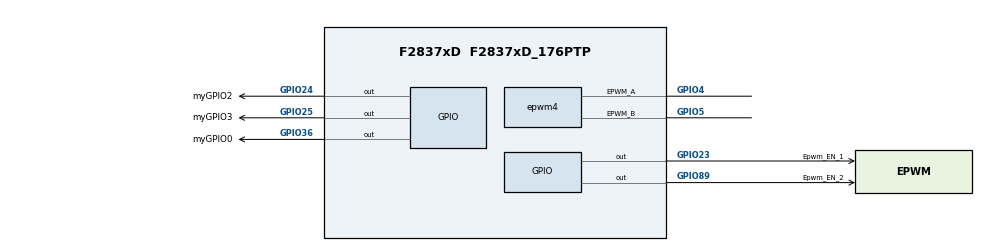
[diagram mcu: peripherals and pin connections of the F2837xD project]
/**
 *
 * @cliArgs --device "F2837xD" --part "F2837xD_176PTP" --package "F2837xD_176PTP" --context "CPU1" --product "C2000WARE@26.01.00.00"
 * @versions {"tool":"1.28.0+4696"}
 */

/**
 * Import the modules used in this configuration.
 */
const adc            = scripting.addModule("/driverlib/adc.js", {}, false);
const adc1           = adc.addInstance();
const adc2           = adc.addInstance();
const adc3           = adc.addInstance();
const device_support = scripting.addModule("/driverlib/device_support.js");
const dma            = scripting.addModule("/driverlib/dma.js", {}, false);
const dma1           = dma.addInstance();
const epwm           = scripting.addModule("/driverlib/epwm.js", {}, false);
const epwm1          = epwm.addInstance();
const epwm2          = epwm.addInstance();
const epwm3          = epwm.addInstance();
const epwm4          = epwm.addInstance();
const epwm5          = epwm.addInstance();
const epwm6          = epwm.addInstance();
const epwm7          = epwm.addInstance();
const gpio           = scripting.addModule("/driverlib/gpio.js", {}, false);
const gpio1          = gpio.addInstance();
const gpio2          = gpio.addInstance();
const gpio3          = gpio.addInstance();
const gpio4          = gpio.addInstance();
const gpio5          = gpio.addInstance();
const sysctl         = scripting.addModule("/driverlib/sysctl.js");
const FPUfastRTS     = scripting.addModule("/libraries/math/FPUfastRTS/FPUfastRTS.js", {}, false);
const FPUfastRTS1    = FPUfastRTS.addInstance();

/**
 * Write custom configuration values to the imported modules.
 */
adc1.$name               = "myADC0";
adc1.adcClockPrescaler   = "ADC_CLK_DIV_4_0";
adc1.enabledSOCs         = ["ADC_SOC_NUMBER2","ADC_SOC_NUMBER3","ADC_SOC_NUMBER4","ADC_SOC_NUMBER5"];
adc1.soc2Channel         = "ADC_CH_ADCIN2";
adc1.soc2SampleWindow    = 15;
adc1.soc2Trigger         = "ADC_TRIGGER_EPWM5_SOCA";
adc1.soc3Channel         = "ADC_CH_ADCIN3";
adc1.soc3SampleWindow    = 15;
adc1.soc3Trigger         = "ADC_TRIGGER_EPWM5_SOCA";
adc1.soc4Channel         = "ADC_CH_ADCIN4";
adc1.soc4SampleWindow    = 15;
adc1.soc4Trigger         = "ADC_TRIGGER_EPWM5_SOCA";
adc1.soc5Channel         = "ADC_CH_ADCIN5";
adc1.soc5SampleWindow    = 15;
adc1.soc5Trigger         = "ADC_TRIGGER_EPWM5_SOCA";
adc1.enableInterrupt1    = true;
adc1.useInterrupts       = false;
adc1.interruptPulseMode  = "ADC_PULSE_END_OF_CONV";
adc1.enabledInts         = ["ADC_INT_NUMBER1"];
adc1.interrupt1SOCSource = "ADC_SOC_NUMBER2";

adc2.$name             = "myADC1";
adc2.adcBase           = "ADCB_BASE";
adc2.adcClockPrescaler = "ADC_CLK_DIV_4_0";
adc2.enabledSOCs       = ["ADC_SOC_NUMBER0","ADC_SOC_NUMBER1"];
adc2.soc0Channel       = "ADC_CH_ADCIN2";
adc2.soc0SampleWindow  = 15;
adc2.soc1Channel       = "ADC_CH_ADCIN3";
adc2.soc1SampleWindow  = 15;
adc2.soc0Trigger       = "ADC_TRIGGER_EPWM5_SOCA";
adc2.soc1Trigger       = "ADC_TRIGGER_EPWM5_SOCA";

adc3.$name             = "myADC2";
adc3.adcBase           = "ADCC_BASE";
adc3.adcClockPrescaler = "ADC_CLK_DIV_4_0";
adc3.enabledSOCs       = ["ADC_SOC_NUMBER0","ADC_SOC_NUMBER1"];
adc3.soc0SampleWindow  = 15;
adc3.soc0Channel       = "ADC_CH_ADCIN2";
adc3.soc1Channel       = "ADC_CH_ADCIN3";
adc3.soc1SampleWindow  = 15;
adc3.soc1Trigger       = "ADC_TRIGGER_EPWM5_SOCA";
adc3.soc0Trigger       = "ADC_TRIGGER_EPWM5_SOCA";

const multiplier4         = system.clockTree["PLL_IMULT"];
multiplier4.multiplyValue = 20;

const pinFunction3     = system.clockTree["XTAL"];
pinFunction3.XTAL_Freq = 20;

dma1.$name                = "myDMA0";
dma1.emulationMode        = "DMA_EMULATION_FREE_RUN";
dma1.startChannel         = true;
dma1.srcBurstStep         = 1;
dma1.srcAddressManual     = 0xB02;
dma1.destAddressInputMode = "VARIABLE";
dma1.destBurstStep        = 1;
dma1.destAddressVariable  = "adc1_DATA_dma";
dma1.srcAddressVariable   = "datafrom";
dma1.srcAddressInputMode  = "VARIABLE";
dma1.burstSize            = 4;
dma1.srcTransferStep      = -4;
dma1.destTransferStep     = -4;
dma1.continuousModeConfig = "DMA_CFG_CONTINUOUS_ENABLE";
dma1.triggerSource        = "DMA_TRIGGER_EPWM5SOCA";

epwm1.epwmTimebase_counterMode                                 = "EPWM_COUNTER_MODE_UP";
epwm1.epwmActionQualifier_EPWM_AQ_OUTPUT_A_shadowMode          = true;
epwm1.epwmActionQualifier_EPWM_AQ_OUTPUT_B_shadowMode          = true;
epwm1.epwmDeadband_enableFED                                   = true;
epwm1.epwmDeadband_polarityFED                                 = "EPWM_DB_POLARITY_ACTIVE_LOW";
epwm1.epwmDeadband_enableRED                                   = true;
epwm1.epwmDeadband_inputFED                                    = "EPWM_DB_INPUT_EPWMB";
epwm1.$name                                                    = "myEPWM1";
epwm1.epwmTimebase_hsClockDiv                                  = "EPWM_HSCLOCK_DIVIDER_1";
epwm1.epwmTimebase_syncOutPulseMode                            = "EPWM_SYNC_OUT_PULSE_ON_COUNTER_ZERO";
epwm1.epwmActionQualifier_EPWM_AQ_OUTPUT_A_ON_TIMEBASE_UP_CMPB = "EPWM_AQ_OUTPUT_HIGH";
epwm1.epwmEventTrigger_enableInterrupt                         = true;
epwm1.epwmEventTrigger_registerInterrupts                      = true;
epwm1.epwmEventTrigger_interruptSource                         = "EPWM_INT_TBCTR_ZERO";
epwm1.epwmCounterCompare_cmpA                                  = 250;
epwm1.epwmCounterCompare_cmpB                                  = 500;
epwm1.epwmEventTrigger_interruptEventCount                     = "4";
epwm1.epwmActionQualifier_EPWM_AQ_OUTPUT_B_ON_TIMEBASE_ZERO    = "EPWM_AQ_OUTPUT_LOW";
epwm1.epwmGlobalLoad_gld                                       = true;
epwm1.epwmGlobalLoad_gldPeriod                                 = "1";
epwm1.epwmGlobalLoad_enableOneShot                             = true;
epwm1.epwmGlobalLoad_oneShotMode                               = true;
epwm1.epwmCounterCompare_cmpAGld                               = true;
epwm1.epwmCounterCompare_cmpBGld                               = true;
epwm1.epwmActionQualifier_continousSwForceReloadModeGld        = true;
epwm1.epwmActionQualifier_EPWM_AQ_OUTPUT_A_gld                 = true;
epwm1.epwmActionQualifier_EPWM_AQ_OUTPUT_B_gld                 = true;
epwm1.epwmActionQualifier_EPWM_AQ_OUTPUT_A_ON_TIMEBASE_ZERO    = "EPWM_AQ_OUTPUT_HIGH";
epwm1.epwmActionQualifier_EPWM_AQ_OUTPUT_A_ON_TIMEBASE_UP_CMPA = "EPWM_AQ_OUTPUT_LOW";
epwm1.epwmActionQualifier_EPWM_AQ_OUTPUT_B_ON_TIMEBASE_UP_CMPA = "EPWM_AQ_OUTPUT_LOW";
epwm1.epwmActionQualifier_EPWM_AQ_OUTPUT_B_ON_TIMEBASE_UP_CMPB = "EPWM_AQ_OUTPUT_HIGH";
epwm1.epwmTimebase_period                                      = 2000;
epwm1.epwmDeadband_delayRED                                    = 10;
epwm1.epwmDeadband_delayFED                                    = 10;
epwm1.epwmGlobalLoad_gldMode                                   = "EPWM_GL_LOAD_PULSE_CNTR_PERIOD";
epwm1.epwmActionQualifier_continousSwForceReloadMode           = "EPWM_AQ_SW_SH_LOAD_ON_CNTR_PERIOD";
epwm1.epwm.$assign                                             = "EPWM1";
epwm1.epwmInt.enableInterrupt                                  = true;

epwm2.$name                                                    = "myEPWM2";
epwm2.epwmTimebase_hsClockDiv                                  = "EPWM_HSCLOCK_DIVIDER_1";
epwm2.epwmTimebase_periodLoadEvent                             = "EPWM_SHADOW_LOAD_MODE_COUNTER_SYNC";
epwm2.epwmTimebase_phaseEnable                                 = true;
epwm2.epwmTimebase_counterMode                                 = "EPWM_COUNTER_MODE_UP";
epwm2.epwmDeadband_inputFED                                    = "EPWM_DB_INPUT_EPWMB";
epwm2.epwmDeadband_polarityFED                                 = "EPWM_DB_POLARITY_ACTIVE_LOW";
epwm2.epwmDeadband_enableRED                                   = true;
epwm2.epwmDeadband_enableFED                                   = true;
epwm2.epwmDeadband_delayRED                                    = 10;
epwm2.epwmDeadband_delayFED                                    = 10;
epwm2.epwmActionQualifier_EPWM_AQ_OUTPUT_A_ON_TIMEBASE_UP_CMPB = "EPWM_AQ_OUTPUT_HIGH";
epwm2.epwmCounterCompare_cmpB                                  = 750;
epwm2.epwmCounterCompare_cmpA                                  = 500;
epwm2.epwmTimebase_syncOutPulseMode                            = "EPWM_SYNC_OUT_PULSE_ON_EPWMxSYNCIN";
epwm2.epwmActionQualifier_EPWM_AQ_OUTPUT_B_ON_TIMEBASE_ZERO    = "EPWM_AQ_OUTPUT_LOW";
epwm2.epwmGlobalLoad_gld                                       = true;
epwm2.epwmGlobalLoad_gldPeriod                                 = "1";
epwm2.epwmGlobalLoad_enableOneShot                             = true;
epwm2.epwmGlobalLoad_oneShotMode                               = true;
epwm2.epwmGlobalLoad_globalePWMLoadLink                        = "EPWM_LINK_WITH_EPWM_1";
epwm2.epwmActionQualifier_EPWM_AQ_OUTPUT_A_shadowMode          = true;
epwm2.epwmActionQualifier_EPWM_AQ_OUTPUT_B_shadowMode          = true;
epwm2.epwmActionQualifier_EPWM_AQ_OUTPUT_A_gld                 = true;
epwm2.epwmActionQualifier_EPWM_AQ_OUTPUT_B_gld                 = true;
epwm2.epwmActionQualifier_continousSwForceReloadModeGld        = true;
epwm2.epwmCounterCompare_cmpAGld                               = true;
epwm2.epwmCounterCompare_cmpBGld                               = true;
epwm2.epwmActionQualifier_EPWM_AQ_OUTPUT_A_ON_TIMEBASE_ZERO    = "EPWM_AQ_OUTPUT_LOW";
epwm2.epwmActionQualifier_EPWM_AQ_OUTPUT_A_ON_TIMEBASE_UP_CMPA = "EPWM_AQ_OUTPUT_HIGH";
epwm2.epwmActionQualifier_EPWM_AQ_OUTPUT_B_ON_TIMEBASE_UP_CMPA = "EPWM_AQ_OUTPUT_HIGH";
epwm2.epwmActionQualifier_EPWM_AQ_OUTPUT_B_ON_TIMEBASE_UP_CMPB = "EPWM_AQ_OUTPUT_LOW";
epwm2.epwmTimebase_period                                      = 2000;
epwm2.epwmGlobalLoad_gldMode                                   = "EPWM_GL_LOAD_PULSE_CNTR_PERIOD";
epwm2.epwm.$assign                                             = "EPWM2";

epwm3.$name                                             = "myEPWM5";
epwm3.epwmTimebase_hsClockDiv                           = "EPWM_HSCLOCK_DIVIDER_1";
epwm3.epwmTimebase_periodLoadEvent                      = "EPWM_SHADOW_LOAD_MODE_COUNTER_SYNC";
epwm3.epwmTimebase_phaseEnable                          = true;
epwm3.epwmTimebase_counterMode                          = "EPWM_COUNTER_MODE_UP";
epwm3.epwmTimebase_syncOutPulseMode                     = "EPWM_SYNC_OUT_PULSE_ON_COUNTER_ZERO";
epwm3.epwmActionQualifier_EPWM_AQ_OUTPUT_A_shadowMode   = true;
epwm3.epwmDeadband_inputFED                             = "EPWM_DB_INPUT_EPWMB";
epwm3.epwmDeadband_polarityFED                          = "EPWM_DB_POLARITY_ACTIVE_LOW";
epwm3.epwmDeadband_enableRED                            = true;
epwm3.epwmDeadband_enableFED                            = true;
epwm3.epwmDeadband_delayRED                             = 10;
epwm3.epwmDeadband_delayFED                             = 10;
epwm3.epwmEventTrigger_EPWM_SOC_A_triggerEnable         = true;
epwm3.epwmCounterCompare_cmpB                           = 1;
epwm3.epwmEventTrigger_EPWM_SOC_A_triggerEventPrescalar = "4";
epwm3.epwmEventTrigger_EPWM_SOC_A_triggerSource         = "EPWM_SOC_TBCTR_U_CMPA";
epwm3.epwmTimebase_period                               = 2000;
epwm3.epwmCounterCompare_cmpA                           = 500;
epwm3.epwm.$assign                                      = "EPWM5";

epwm4.$name                                                    = "myEPWM3";
epwm4.epwmTimebase_counterMode                                 = "EPWM_COUNTER_MODE_UP";
epwm4.epwmActionQualifier_EPWM_AQ_OUTPUT_A_shadowMode          = true;
epwm4.epwmActionQualifier_EPWM_AQ_OUTPUT_B_shadowMode          = true;
epwm4.epwmDeadband_enableFED                                   = true;
epwm4.epwmDeadband_polarityFED                                 = "EPWM_DB_POLARITY_ACTIVE_LOW";
epwm4.epwmDeadband_enableRED                                   = true;
epwm4.epwmDeadband_inputFED                                    = "EPWM_DB_INPUT_EPWMB";
epwm4.epwmDeadband_delayRED                                    = 10;
epwm4.epwmDeadband_delayFED                                    = 10;
epwm4.epwmTimebase_hsClockDiv                                  = "EPWM_HSCLOCK_DIVIDER_1";
epwm4.epwmActionQualifier_EPWM_AQ_OUTPUT_A_ON_TIMEBASE_UP_CMPB = "EPWM_AQ_OUTPUT_HIGH";
epwm4.epwmCounterCompare_cmpA                                  = 250;
epwm4.epwmCounterCompare_cmpB                                  = 500;
epwm4.epwmActionQualifier_EPWM_AQ_OUTPUT_B_ON_TIMEBASE_ZERO    = "EPWM_AQ_OUTPUT_LOW";
epwm4.epwmGlobalLoad_gld                                       = true;
epwm4.epwmGlobalLoad_gldPeriod                                 = "1";
epwm4.epwmGlobalLoad_enableOneShot                             = true;
epwm4.epwmGlobalLoad_oneShotMode                               = true;
epwm4.epwmCounterCompare_cmpAGld                               = true;
epwm4.epwmCounterCompare_cmpBGld                               = true;
epwm4.epwmActionQualifier_continousSwForceReloadModeGld        = true;
epwm4.epwmActionQualifier_EPWM_AQ_OUTPUT_A_gld                 = true;
epwm4.epwmActionQualifier_EPWM_AQ_OUTPUT_B_gld                 = true;
epwm4.epwmGlobalLoad_globalePWMLoadLink                        = "EPWM_LINK_WITH_EPWM_1";
epwm4.epwmTimebase_phaseEnable                                 = true;
epwm4.epwmTimebase_syncOutPulseMode                            = "EPWM_SYNC_OUT_PULSE_ON_EPWMxSYNCIN";
epwm4.epwmActionQualifier_EPWM_AQ_OUTPUT_A_ON_TIMEBASE_ZERO    = "EPWM_AQ_OUTPUT_HIGH";
epwm4.epwmActionQualifier_EPWM_AQ_OUTPUT_A_ON_TIMEBASE_UP_CMPA = "EPWM_AQ_OUTPUT_LOW";
epwm4.epwmActionQualifier_EPWM_AQ_OUTPUT_B_ON_TIMEBASE_UP_CMPA = "EPWM_AQ_OUTPUT_LOW";
epwm4.epwmActionQualifier_EPWM_AQ_OUTPUT_B_ON_TIMEBASE_UP_CMPB = "EPWM_AQ_OUTPUT_HIGH";
epwm4.epwmTimebase_period                                      = 2000;
epwm4.epwmTimebase_phaseShift                                  = 667;
epwm4.epwmGlobalLoad_gldMode                                   = "EPWM_GL_LOAD_PULSE_CNTR_PERIOD";
epwm4.epwm.epwm_aPin.$assign                                   = "GPIO4";
epwm4.epwm.epwm_bPin.$assign                                   = "GPIO5";

epwm5.$name                                                    = "myEPWM4";
epwm5.epwmTimebase_hsClockDiv                                  = "EPWM_HSCLOCK_DIVIDER_1";
epwm5.epwmTimebase_periodLoadEvent                             = "EPWM_SHADOW_LOAD_MODE_COUNTER_SYNC";
epwm5.epwmTimebase_phaseEnable                                 = true;
epwm5.epwmTimebase_counterMode                                 = "EPWM_COUNTER_MODE_UP";
epwm5.epwmDeadband_inputFED                                    = "EPWM_DB_INPUT_EPWMB";
epwm5.epwmDeadband_polarityFED                                 = "EPWM_DB_POLARITY_ACTIVE_LOW";
epwm5.epwmDeadband_enableRED                                   = true;
epwm5.epwmDeadband_enableFED                                   = true;
epwm5.epwmDeadband_delayRED                                    = 10;
epwm5.epwmDeadband_delayFED                                    = 10;
epwm5.epwmActionQualifier_EPWM_AQ_OUTPUT_A_ON_TIMEBASE_UP_CMPB = "EPWM_AQ_OUTPUT_HIGH";
epwm5.epwmCounterCompare_cmpB                                  = 750;
epwm5.epwmCounterCompare_cmpA                                  = 500;
epwm5.epwmTimebase_syncOutPulseMode                            = "EPWM_SYNC_OUT_PULSE_ON_EPWMxSYNCIN";
epwm5.epwmActionQualifier_EPWM_AQ_OUTPUT_B_ON_TIMEBASE_ZERO    = "EPWM_AQ_OUTPUT_LOW";
epwm5.epwmGlobalLoad_gld                                       = true;
epwm5.epwmGlobalLoad_gldPeriod                                 = "1";
epwm5.epwmGlobalLoad_enableOneShot                             = true;
epwm5.epwmGlobalLoad_oneShotMode                               = true;
epwm5.epwmGlobalLoad_globalePWMLoadLink                        = "EPWM_LINK_WITH_EPWM_1";
epwm5.epwmActionQualifier_EPWM_AQ_OUTPUT_A_shadowMode          = true;
epwm5.epwmActionQualifier_EPWM_AQ_OUTPUT_B_shadowMode          = true;
epwm5.epwmActionQualifier_EPWM_AQ_OUTPUT_A_gld                 = true;
epwm5.epwmActionQualifier_EPWM_AQ_OUTPUT_B_gld                 = true;
epwm5.epwmActionQualifier_continousSwForceReloadModeGld        = true;
epwm5.epwmCounterCompare_cmpAGld                               = true;
epwm5.epwmCounterCompare_cmpBGld                               = true;
epwm5.epwmActionQualifier_EPWM_AQ_OUTPUT_A_ON_TIMEBASE_ZERO    = "EPWM_AQ_OUTPUT_LOW";
epwm5.epwmActionQualifier_EPWM_AQ_OUTPUT_A_ON_TIMEBASE_UP_CMPA = "EPWM_AQ_OUTPUT_HIGH";
epwm5.epwmActionQualifier_EPWM_AQ_OUTPUT_B_ON_TIMEBASE_UP_CMPA = "EPWM_AQ_OUTPUT_HIGH";
epwm5.epwmActionQualifier_EPWM_AQ_OUTPUT_B_ON_TIMEBASE_UP_CMPB = "EPWM_AQ_OUTPUT_LOW";
epwm5.epwmTimebase_period                                      = 2000;
epwm5.epwmTimebase_phaseShift                                  = 667;
epwm5.epwmGlobalLoad_gldMode                                   = "EPWM_GL_LOAD_PULSE_CNTR_PERIOD";
epwm5.epwm.$assign                                             = "EPWM4";

epwm6.epwmTimebase_counterMode                                 = "EPWM_COUNTER_MODE_UP";
epwm6.epwmActionQualifier_EPWM_AQ_OUTPUT_A_shadowMode          = true;
epwm6.epwmActionQualifier_EPWM_AQ_OUTPUT_B_shadowMode          = true;
epwm6.epwmDeadband_enableFED                                   = true;
epwm6.epwmDeadband_polarityFED                                 = "EPWM_DB_POLARITY_ACTIVE_LOW";
epwm6.epwmDeadband_enableRED                                   = true;
epwm6.epwmDeadband_inputFED                                    = "EPWM_DB_INPUT_EPWMB";
epwm6.epwmDeadband_delayRED                                    = 10;
epwm6.epwmDeadband_delayFED                                    = 10;
epwm6.$name                                                    = "myEPWM6";
epwm6.epwmTimebase_hsClockDiv                                  = "EPWM_HSCLOCK_DIVIDER_1";
epwm6.epwmTimebase_syncOutPulseMode                            = "EPWM_SYNC_OUT_PULSE_ON_COUNTER_ZERO";
epwm6.epwmActionQualifier_EPWM_AQ_OUTPUT_A_ON_TIMEBASE_UP_CMPB = "EPWM_AQ_OUTPUT_HIGH";
epwm6.epwmCounterCompare_cmpA                                  = 250;
epwm6.epwmCounterCompare_cmpB                                  = 500;
epwm6.epwmActionQualifier_EPWM_AQ_OUTPUT_B_ON_TIMEBASE_ZERO    = "EPWM_AQ_OUTPUT_LOW";
epwm6.epwmGlobalLoad_gld                                       = true;
epwm6.epwmGlobalLoad_gldPeriod                                 = "1";
epwm6.epwmGlobalLoad_enableOneShot                             = true;
epwm6.epwmGlobalLoad_oneShotMode                               = true;
epwm6.epwmCounterCompare_cmpAGld                               = true;
epwm6.epwmCounterCompare_cmpBGld                               = true;
epwm6.epwmActionQualifier_continousSwForceReloadModeGld        = true;
epwm6.epwmActionQualifier_EPWM_AQ_OUTPUT_A_gld                 = true;
epwm6.epwmActionQualifier_EPWM_AQ_OUTPUT_B_gld                 = true;
epwm6.epwmGlobalLoad_globalePWMLoadLink                        = "EPWM_LINK_WITH_EPWM_1";
epwm6.epwmTimebase_phaseEnable                                 = true;
epwm6.epwmActionQualifier_EPWM_AQ_OUTPUT_A_ON_TIMEBASE_ZERO    = "EPWM_AQ_OUTPUT_HIGH";
epwm6.epwmActionQualifier_EPWM_AQ_OUTPUT_A_ON_TIMEBASE_UP_CMPA = "EPWM_AQ_OUTPUT_LOW";
epwm6.epwmActionQualifier_EPWM_AQ_OUTPUT_B_ON_TIMEBASE_UP_CMPA = "EPWM_AQ_OUTPUT_LOW";
epwm6.epwmActionQualifier_EPWM_AQ_OUTPUT_B_ON_TIMEBASE_UP_CMPB = "EPWM_AQ_OUTPUT_HIGH";
epwm6.epwmTimebase_period                                      = 2000;
epwm6.epwmTimebase_phaseShift                                  = 1333;
epwm6.epwmGlobalLoad_gldMode                                   = "EPWM_GL_LOAD_PULSE_CNTR_PERIOD";
epwm6.epwm.$assign                                             = "EPWM6";

epwm7.$name                                                    = "myEPWM7";
epwm7.epwmTimebase_hsClockDiv                                  = "EPWM_HSCLOCK_DIVIDER_1";
epwm7.epwmTimebase_periodLoadEvent                             = "EPWM_SHADOW_LOAD_MODE_COUNTER_SYNC";
epwm7.epwmTimebase_phaseEnable                                 = true;
epwm7.epwmTimebase_counterMode                                 = "EPWM_COUNTER_MODE_UP";
epwm7.epwmDeadband_inputFED                                    = "EPWM_DB_INPUT_EPWMB";
epwm7.epwmDeadband_polarityFED                                 = "EPWM_DB_POLARITY_ACTIVE_LOW";
epwm7.epwmDeadband_enableRED                                   = true;
epwm7.epwmDeadband_enableFED                                   = true;
epwm7.epwmDeadband_delayRED                                    = 10;
epwm7.epwmDeadband_delayFED                                    = 10;
epwm7.epwmActionQualifier_EPWM_AQ_OUTPUT_A_ON_TIMEBASE_UP_CMPB = "EPWM_AQ_OUTPUT_HIGH";
epwm7.epwmCounterCompare_cmpB                                  = 750;
epwm7.epwmCounterCompare_cmpA                                  = 500;
epwm7.epwmTimebase_syncOutPulseMode                            = "EPWM_SYNC_OUT_PULSE_ON_EPWMxSYNCIN";
epwm7.epwmActionQualifier_EPWM_AQ_OUTPUT_B_ON_TIMEBASE_ZERO    = "EPWM_AQ_OUTPUT_LOW";
epwm7.epwmGlobalLoad_gld                                       = true;
epwm7.epwmGlobalLoad_gldPeriod                                 = "1";
epwm7.epwmGlobalLoad_enableOneShot                             = true;
epwm7.epwmGlobalLoad_oneShotMode                               = true;
epwm7.epwmGlobalLoad_globalePWMLoadLink                        = "EPWM_LINK_WITH_EPWM_1";
epwm7.epwmActionQualifier_EPWM_AQ_OUTPUT_A_shadowMode          = true;
epwm7.epwmActionQualifier_EPWM_AQ_OUTPUT_B_shadowMode          = true;
epwm7.epwmActionQualifier_EPWM_AQ_OUTPUT_A_gld                 = true;
epwm7.epwmActionQualifier_EPWM_AQ_OUTPUT_B_gld                 = true;
epwm7.epwmActionQualifier_continousSwForceReloadModeGld        = true;
epwm7.epwmCounterCompare_cmpAGld                               = true;
epwm7.epwmCounterCompare_cmpBGld                               = true;
epwm7.epwmActionQualifier_EPWM_AQ_OUTPUT_A_ON_TIMEBASE_ZERO    = "EPWM_AQ_OUTPUT_LOW";
epwm7.epwmActionQualifier_EPWM_AQ_OUTPUT_A_ON_TIMEBASE_UP_CMPA = "EPWM_AQ_OUTPUT_HIGH";
epwm7.epwmActionQualifier_EPWM_AQ_OUTPUT_B_ON_TIMEBASE_UP_CMPA = "EPWM_AQ_OUTPUT_HIGH";
epwm7.epwmActionQualifier_EPWM_AQ_OUTPUT_B_ON_TIMEBASE_UP_CMPB = "EPWM_AQ_OUTPUT_LOW";
epwm7.epwmTimebase_period                                      = 2000;
epwm7.epwmTimebase_phaseShift                                  = 1333;
epwm7.epwmGlobalLoad_gldMode                                   = "EPWM_GL_LOAD_PULSE_CNTR_PERIOD";
epwm7.epwm.$assign                                             = "EPWM7";

gpio1.$name           = "myGPIO0";
gpio1.direction       = "GPIO_DIR_MODE_OUT";
gpio1.gpioPin.$assign = "GPIO36";

gpio2.direction       = "GPIO_DIR_MODE_OUT";
gpio2.$name           = "Epwm_EN_1";
gpio2.gpioPin.$assign = "GPIO23";

gpio3.$name           = "myGPIO2";
gpio3.direction       = "GPIO_DIR_MODE_OUT";
gpio3.gpioPin.$assign = "GPIO24";

gpio4.$name           = "myGPIO3";
gpio4.direction       = "GPIO_DIR_MODE_OUT";
gpio4.gpioPin.$assign = "GPIO25";

gpio5.direction       = "GPIO_DIR_MODE_OUT";
gpio5.$name           = "Epwm_EN_2";
gpio5.gpioPin.$assign = "GPIO89";

sysctl.splitCode = true;

FPUfastRTS1.$name = "myFFR0";

/**
 * Pinmux solution for unlocked pins/peripherals. This ensures that minor changes to the automatic solver in a future
 * version of the tool will not impact the pinmux you originally saw.  These lines can be completely deleted in order to
 * re-solve from scratch.
 */
epwm1.epwm.epwm_aPin.$suggestSolution = "GPIO0";
epwm1.epwm.epwm_bPin.$suggestSolution = "GPIO1";
epwm2.epwm.epwm_aPin.$suggestSolution = "GPIO2";
epwm2.epwm.epwm_bPin.$suggestSolution = "GPIO3";
epwm3.epwm.epwm_aPin.$suggestSolution = "GPIO8";
epwm3.epwm.epwm_bPin.$suggestSolution = "GPIO9";
epwm4.epwm.$suggestSolution           = "EPWM3";
epwm5.epwm.epwm_aPin.$suggestSolution = "GPIO6";
epwm5.epwm.epwm_bPin.$suggestSolution = "GPIO7";
epwm6.epwm.epwm_aPin.$suggestSolution = "GPIO10";
epwm6.epwm.epwm_bPin.$suggestSolution = "GPIO11";
epwm7.epwm.epwm_aPin.$suggestSolution = "GPIO12";
epwm7.epwm.epwm_bPin.$suggestSolution = "GPIO13";
